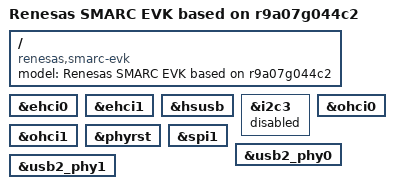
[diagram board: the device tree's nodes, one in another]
// SPDX-License-Identifier: (GPL-2.0-only OR BSD-2-Clause)
/*
 * Device Tree Source for the RZ/G2LC SMARC EVK board
 *
 * Copyright (C) 2021 Renesas Electronics Corp.
 */

/dts-v1/;
#include "r9a07g044c2.dtsi"
#include "rzg2lc-smarc.dtsi"

/ {
	model = "Renesas SMARC EVK based on r9a07g044c2";
	compatible = "renesas,smarc-evk", "renesas,r9a07g044c2", "renesas,r9a07g044";
};

&ehci0 {
	/delete-property/ pinctrl-0;
	/delete-property/ pinctrl-names;
	status = "okay";
};

&ehci1 {
	/delete-property/ pinctrl-0;
	/delete-property/ pinctrl-names;
	status = "okay";
};

&hsusb {
	/delete-property/ pinctrl-0;
	/delete-property/ pinctrl-names;
	status = "okay";
};

&i2c3 {
	/delete-property/ pinctrl-0;
	/delete-property/ pinctrl-names;
	status = "disabled";
};

&ohci0 {
	/delete-property/ pinctrl-0;
	/delete-property/ pinctrl-names;
	status = "okay";
};

&ohci1 {
	/delete-property/ pinctrl-0;
	/delete-property/ pinctrl-names;
	status = "okay";
};

&phyrst {
	status = "okay";
};

&spi1 {
	/delete-property/ pinctrl-0;
	/delete-property/ pinctrl-names;
	status = "okay";
};

&usb2_phy0 {
	/delete-property/ pinctrl-0;
	/delete-property/ pinctrl-names;
	status = "okay";
};

&usb2_phy1 {
	/delete-property/ pinctrl-0;
	/delete-property/ pinctrl-names;
	status = "okay";
};
